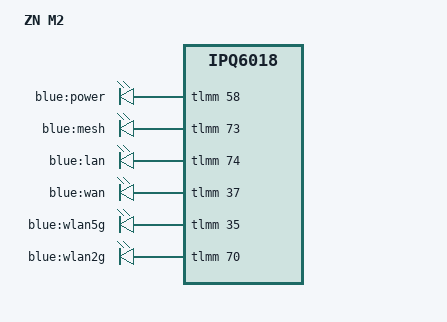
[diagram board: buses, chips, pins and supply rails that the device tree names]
// SPDX-License-Identifier: GPL-2.0-or-later OR MIT

/dts-v1/;

#include "ipq6000-cmiot.dtsi"

/ {
	model = "ZN M2";
	compatible = "zn,m2", "qcom,ipq6018";

	aliases {
		led-boot = &led_power;
		led-failsafe = &led_power;
		led-running = &led_power;
		led-upgrade = &led_power;
	};

	leds {
		compatible = "gpio-leds";

		led_power: power {
			label = "blue:power";
			gpios = <&tlmm 58 GPIO_ACTIVE_HIGH>;
		};

		mesh {
			label = "blue:mesh";
			gpios = <&tlmm 73 GPIO_ACTIVE_HIGH>;
		};

		lan {
			label = "blue:lan";
			gpios = <&tlmm 74 GPIO_ACTIVE_HIGH>;
		};

		wan {
			label = "blue:wan";
			gpios = <&tlmm 37 GPIO_ACTIVE_HIGH>;
		};

		wlan5g {
			label = "blue:wlan5g";
			gpios = <&tlmm 35 GPIO_ACTIVE_HIGH>;
		};

		wlan2g {
			label = "blue:wlan2g";
			gpios = <&tlmm 70 GPIO_ACTIVE_HIGH>;
		};
	};
};

// ================== 彻底禁用 Wi-Fi 和 Q6 DSP ==================

// 1. 禁用 Wi-Fi 设备 (标签存在，可用)
&wifi {
    status = "disabled";
};

// 2. 禁用 Q6 远程处理器 (标签通常存在，若报错可改用路径)
&q6v5_wcss {
    status = "disabled";
};

/ {
    soc@0 {
        remoteproc@cd00000 {
            status = "disabled";
        };
    };
};

// 5. 通过绝对路径删除 Q6 ETR 和 M3 转储保留内存
/ {
    reserved-memory {
        /delete-node/ q6_etr_dump@50b00000;
        /delete-node/ m3_dump@50c00000;
    };
};
